# AVR16EB32 device description
Architecture: AVR8X; Family: AVREB
Registers are 8-bit, read-write, reset 0x0 unless marked. A register's access mark holds for its fields unless they carry their own. Offsets are from the block's base; [hi:lo] are bit positions; {n}, {i} and the like mark numbered series; 'fields as' and 'values as' point back to an identical list.

## GPR — General Purpose Registers
Instances: GPR 0x001C
{0x0+i} GPR{i} reset not defined (i=0..3) — General Purpose Register {i}

## LOCK — Lockbits
Instances: LOCK 0x1040
0x00 KEY 32-bit reset 0x5CC5C55C — Lock Key Bits
  [31:0] KEY — Lock Key
    0x5CC5C55C=NOLOCK (No locks); 0xA33A3AA3=RWLOCK (Read and write lock)

## NVMCTRL — Non-volatile Memory Controller
Instances: NVMCTRL 0x1000
0x00 CTRLA — Control A
  [6:0] CMD — Command
    0=NOCMD (No Command); 1=NOOP (No Operation); 4=FLPW (Flash Page Write); 5=FLPERW (Flash Page Erase and Write); 8=FLPER (Flash Page Erase); 9=FLMPER2 (Flash 2-page erase enable); 10=FLMPER4 (Flash 4-page erase enable); 11=FLMPER8 (Flash 8-page erase enable); 12=FLMPER16 (Flash 16-page erase enable); 13=FLMPER32 (Flash 32-page erase enable); 15=FLPBCLR (Flash Page Buffer Clear); 20=EEPW (EEPROM Page Write); 21=EEPERW (EEPROM Page Erase and Write); 23=EEPER (EEPROM Page Erase); 31=EEPBCLR (EEPROM Page Buffer Clear); 32=CHER (Chip Erase Command (UPDI only)); 48=EECHER (EEPROM Erase Command (UPDI only))
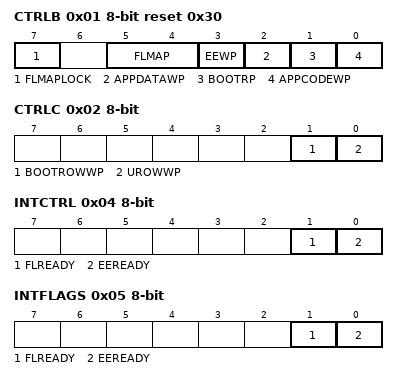
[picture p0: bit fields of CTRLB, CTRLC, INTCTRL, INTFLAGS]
0x01 CTRLB reset 0x30 — Control B
  [7] FLMAPLOCK — Flash Mapping Lock
  [5:4] FLMAP — Flash Mapping in Data space
    0=SECTION0 (Flash section 0, 0 - 32KB); 1=SECTION1 (Flash section 1, 32 - 64KB); 2=SECTION2 (Flash section 2, 64 - 96KB); 3=SECTION3 (Flash section 3, 96 - 128KB)
  [3] EEWP — EEPROM Write Protect
  [2] APPDATAWP — Application Data Write Protect
  [1] BOOTRP — Boot Read Protect
  [0] APPCODEWP — Application Code Write Protect
0x02 CTRLC — Control C
  [1] BOOTROWWP — Boot Row Write Protect
  [0] UROWWP — User Row Write Protect
0x04 INTCTRL — Interrupt Control
  [1] FLREADY — Flash Ready
  [0] EEREADY — EEPROM Ready
0x05 INTFLAGS — Interrupt Flags
  [1] FLREADY — Flash Ready
  [0] EEREADY — EEPROM Ready
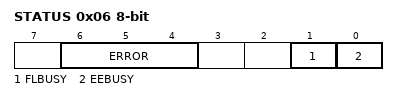
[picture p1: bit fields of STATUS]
0x06 STATUS
  [6:4] ERROR — Write error
    0=NOERROR; 2=WRITEPROTECT (Attempt to program write protected area); 3=CMDCOLLISION (Selecting new write command while write command already seleted); 4=WRONGSECTION (Address cannot be written with selected command)
  [1] FLBUSY ro — Flash busy
  [0] EEBUSY ro — EEPROM busy
0x08 DATA 16-bit
0x0C ADDR 32-bit — Address
  [23:0] ADDR

## PORT — I/O Ports
Instances: PORTA 0x0400, PORTC 0x0440, PORTD 0x0460, PORTF 0x04A0
0x00 DIR — Data Direction
0x01 DIRSET — Data Direction Set
0x02 DIRCLR — Data Direction Clear
0x03 DIRTGL — Data Direction Toggle
0x04 OUT — Output Value
0x05 OUTSET — Output Value Set
0x06 OUTCLR — Output Value Clear
0x07 OUTTGL — Output Value Toggle
0x08 IN — Input Value
0x09 INTFLAGS — Interrupt Flags
  [7:0] INT — Pin Interrupt Flag
0x0A PORTCTRL — Port Control
  [0] SRL — Slew Rate Limit Enable
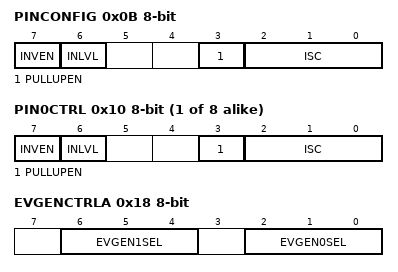
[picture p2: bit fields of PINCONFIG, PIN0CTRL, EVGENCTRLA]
0x0B PINCONFIG — Pin Control Config
  [7] INVEN — Inverted I/O Enable
  [6] INLVL — Input Level Select
    0=ST (Schmitt-Trigger input level); 1=TTL (TTL Input level)
  [3] PULLUPEN — Pullup enable
  [2:0] ISC — Input/Sense Configuration
    0=INTDISABLE (Interrupt disabled but input buffer enabled); 1=BOTHEDGES (Sense Both Edges); 2=RISING (Sense Rising Edge); 3=FALLING (Sense Falling Edge); 4=INPUT_DISABLE (Digital Input Buffer disabled); 5=LEVEL (Sense low Level)
0x0C PINCTRLUPD — Pin Control Update
0x0D PINCTRLSET — Pin Control Set
0x0E PINCTRLCLR — Pin Control Clear
{0x10+i} PIN{i}CTRL (i=0..7) — Pin {i} Control
  fields as PINCONFIG
0x18 EVGENCTRLA — Event Generation Control A
  [6:4] EVGEN1SEL — Event Generator 1 Select
    {v}=PIN{v} (Pin {v} used as event generator) (v=0..7)
  [2:0] EVGEN0SEL — Event Generator 0 Select
    {v}=PIN{v} (Pin {v} used as event generator) (v=0..7)

## PORTMUX — Port Multiplexer
Instances: PORTMUX 0x05E0
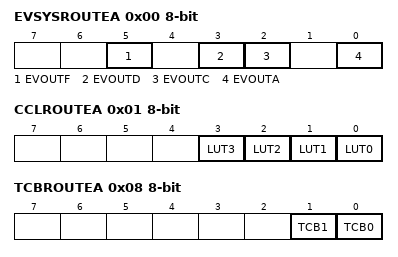
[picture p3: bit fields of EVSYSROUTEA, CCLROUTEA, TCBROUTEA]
0x00 EVSYSROUTEA
  [5] EVOUTF — Event Output F
    0=DEFAULT (EVOUT on PF2); 1=ALT1 (EVOUT on PF7)
  [3] EVOUTD — Event Output D
    0=DEFAULT (EVOUT on PD2); 1=ALT1 (EVOUT on PD7)
  [2] EVOUTC — Event Output C
    0=DEFAULT (EVOUT on PC2)
  [0] EVOUTA — Event Output A
    0=DEFAULT (EVOUT on PA2); 1=ALT1 (EVOUT on PA7)
0x01 CCLROUTEA
  [3] LUT3 — CCL Look-Up Table 3 Signals
    0=DEFAULT (Out: PF3 In: PF0, PF1, PF2)
  [2] LUT2 — CCL Look-Up Table 2 Signals
    0=DEFAULT (Out: PD3 In: PD0, PD1, PD2); 1=ALT1 (Out: PD6 In: PD0, PD1, PD2)
  [1] LUT1 — CCL Look-Up Table 1 Signals
    0=DEFAULT (Out: PC3 In: PC0, PC1, PC2)
  [0] LUT0 — CCL Look-Up Table 0 Signals
    0=DEFAULT (Out: PA3 In: PA0, PA1, PA2); 1=ALT1 (Out: PA6 In: PA0, PA1, PA2)
0x02 USARTROUTEA
  [2:0] USART0 — USART0 Routing
    0=DEFAULT ({PA0, PA1, PA2, PA3}); 1=ALT1 ({PA4, PA5, PA6, PA7}); 2=ALT2 ({PA2,PA3, -, -}); 3=ALT3 ({PD4, PD5, PD6, PD7}); 4=ALT4 ({PC1, PC2, PC3, -}); 6=ALT6 ({PF7, PF6, -, -}); 7=NONE (Not connected to any pins)
0x05 SPIROUTEA
  [2:0] SPI0 — SPI0 Signals
    0=DEFAULT (PA4, PA5, PA6, PA7); 3=ALT3 (PA0, PA1, PC0, PC1); 4=ALT4 (PD4, PD5, PD6, PD7); 5=ALT5 (PC0, PC1, PC2, PC3); 6=ALT6 (PC1, PC2, PC3, -); 7=NONE (Not connected to any pins, SS set to 1)
0x06 TWIROUTEA
  [1:0] TWI0 — TWI0 Signals
    0=DEFAULT ({PA2, PA3}, {PC2, PC3}); 2=ALT2 ({PC2, PC3}, {-, -}); 3=ALT3 ({PA0, PA1}, {PC2, PC3})
0x07 TCEROUTEA
  [3:0] TCE0 — TCE0 Signals
    0=PORTA (PA0, PA1, PA2, PA3, PA4, PA5, PA6, PA7); 2=PORTC (PC0, PC1, PC2, PC3, -, -, -, -); 3=PORTD (PD0, PD1, PD2, PD3, PD4, PD5, PD6, PD7); 5=PORTF (PF0, PF1, PF2, PF3, PF4, PF5, -, -); 8=PORTC2 (PA0, PA1, PC0, PC1, PC2, PC3, -, -)
0x08 TCBROUTEA
  [1] TCB1 — TCB1 Output
    0=DEFAULT (PA3); 1=ALT1 (PF5)
  [0] TCB0 — TCB0 Output
    0=DEFAULT (PA2); 1=ALT1 (PF4)
0x0C TCFROUTEA
  [1:0] TCF0 — TCF0 Output
    0=DEFAULT (PA0, PA1); 1=ALT1 (PA6, PA7); 2=ALT2 (PF4, PF5)
